# ATtiny167 register map
Vendor: Atmel; File version: 1.0
CPU: other r0p0, little endian, no MPU, no FPU, 4 interrupt priority bits
Registers are 8-bit, read-write, reset 0x0 unless marked. A register's access mark holds for its fields unless they carry their own. Offsets are from the block's base; [hi:lo] are bit positions.

## LINUART — Local Interconnect Network
Base 0x008000C8
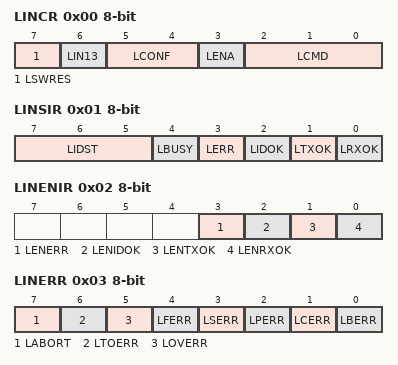
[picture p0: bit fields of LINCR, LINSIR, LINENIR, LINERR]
0x00 LINCR — LIN Control Register
  [7] LSWRES — Software Reset
  [6] LIN13 — LIN Standard
  [5:4] LCONF — LIN Configuration bits
  [3] LENA — LIN or UART Enable
  [2:0] LCMD — LIN Command and Mode bits
0x01 LINSIR — LIN Status and Interrupt Register
  [7:5] LIDST — Identifier Status bits
  [4] LBUSY — Busy Signal
  [3] LERR — Error Interrupt
  [2] LIDOK — Identifier Interrupt
  [1] LTXOK — Transmit Performed Interrupt
  [0] LRXOK — Receive Performed Interrupt
0x02 LINENIR — LIN Enable Interrupt Register
  [3] LENERR — Enable Error Interrupt
  [2] LENIDOK — Enable Identifier Interrupt
  [1] LENTXOK — Enable Transmit Performed Interrupt
  [0] LENRXOK — Enable Receive Performed Interrupt
0x03 LINERR — LIN Error Register (read-only for debugger)
  [7] LABORT — Abort Flag
  [6] LTOERR — Frame Time Out Error Flag
  [5] LOVERR — Overrun Error Flag
  [4] LFERR — Framing Error Flag
  [3] LSERR — Synchronization Error Flag
  [2] LPERR — Parity Error Flag
  [1] LCERR — Checksum Error Flag
  [0] LBERR — Bit Error Flag
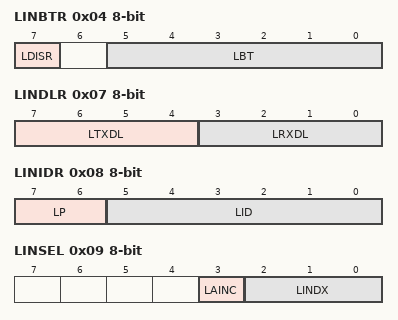
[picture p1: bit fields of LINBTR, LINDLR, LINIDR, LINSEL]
0x04 LINBTR — LIN Bit Timing Register
  [7] LDISR — Disable Bit Timing Resynchronization
  [5:0] LBT — LIN Bit Timing bits
0x05 LINBRRL — LIN Baud Rate Low Register
  [7:0] LDIV
0x06 LINBRRH — LIN Baud Rate High Register
  [3:0] LDIV
0x07 LINDLR — LIN Data Length Register
  [7:4] LTXDL — LIN Transmit Data Length bits
  [3:0] LRXDL — LIN Receive Data Length bits
0x08 LINIDR — LIN Identifier Register
  [7:6] LP — Parity bits
  [5:0] LID — Identifier bit 5 or Data Length bits
0x09 LINSEL — LIN Data Buffer Selection Register
  [3] LAINC — Auto Increment of Data Buffer Index (Active Low)
  [2:0] LINDX — FIFO LIN Data Buffer Index bits
0x0A LINDAT — LIN Data Register (write-only for debugger)
  [7:0] LDATA

## PORTA — I/O Port
Base 0x00800020
0x00 PINA — Port A Input Pins (read-only for debugger)
0x01 DDRA — Port A Data Direction Register
0x02 PORTA — Port A Data Register

## PORTB — I/O Port
Base 0x00800023
0x00 PINB — Port B Input Pins (read-only for debugger)
0x01 DDRB — Port B Data Direction Register
0x02 PORTB — Port B Data Register

## SPI — Serial Peripheral Interface
Base 0x0080004C
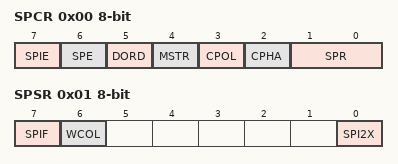
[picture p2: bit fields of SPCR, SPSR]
0x00 SPCR — SPI Control Register
  [7] SPIE — SPI Interrupt Enable
  [6] SPE — SPI Enable
  [5] DORD — Data Order
  [4] MSTR — Master/Slave Select
  [3] CPOL — Clock polarity
  [2] CPHA — Clock Phase
  [1:0] SPR — SPI Clock Rate Selects
    0=FOSC_4; 1=FOSC_16; 3=FOSC_128
0x01 SPSR — SPI Status Register (read-only for debugger)
  [7] SPIF — SPI Interrupt Flag
  [6] WCOL — Write Collision Flag
  [0] SPI2X — Double SPI Speed Bit
0x02 SPDR — SPI Data Register (write-only for debugger)

## TC0 — Timer/Counter, 8-bit Async
Base 0x00800035
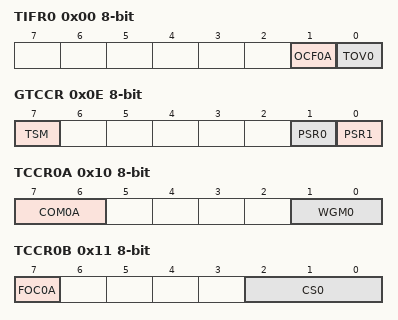
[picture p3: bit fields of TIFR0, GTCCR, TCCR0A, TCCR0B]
0x00 TIFR0 — Timer/Counter0 Interrupt Flag Register (read-only for debugger)
  [1] OCF0A — Output Compare Flag 0A
  [0] TOV0 — Timer/Counter0 Overflow Flag
0x0E GTCCR — General Timer Counter Control register
  [7] TSM — Timer/Counter Synchronization Mode
  [1] PSR0 — Prescaler Reset Asynchronous 8-bit Timer/Counter0
  [0] PSR1 — Prescaler Reset Synchronous 16-bit Timer/Counter1
0x10 TCCR0A — Timer/Counter0 Control Register A
  [7:6] COM0A — Compare Output Mode bits
  [1:0] WGM0 — Waveform Generation Mode bits
0x11 TCCR0B — Timer/Counter0 Control Register B
  [7] FOC0A — Force Output Compare A
  [2:0] CS0 — Clock Select bits
    0=NO_CLOCK_SOURCE_STOPPED; 1=RUNNING_NO_PRESCALING; 2=RUNNING_CLK_8; 3=RUNNING_CLK_32; 4=RUNNING_CLK_64; 5=RUNNING_CLK_128; 6=RUNNING_CLK_256; 7=RUNNING_CLK_1024
0x12 TCNT0 — Timer/Counter0
0x13 OCR0A — Timer/Counter0 Output Compare Register A
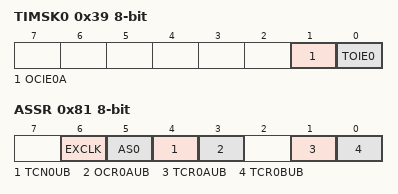
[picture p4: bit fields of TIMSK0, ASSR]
0x39 TIMSK0 — Timer/Counter0 Interrupt Mask register
  [1] OCIE0A — Timer/Counter0 Output Compare Match A Interrupt Enable
  [0] TOIE0 — Timer/Counter0 Overflow Interrupt Enable
0x81 ASSR — Asynchronous Status Register
  [6] EXCLK — Enable External Clock Input
  [5] AS0 — Asynchronous Timer/Counter0
  [4] TCN0UB — Timer/Counter0 Update Busy
  [3] OCR0AUB — Output Compare Register 0A Update Busy
  [1] TCR0AUB — Timer/Counter0 Control Register A Update Busy
  [0] TCR0BUB — Timer/Counter0 Control Register B Update Busy
